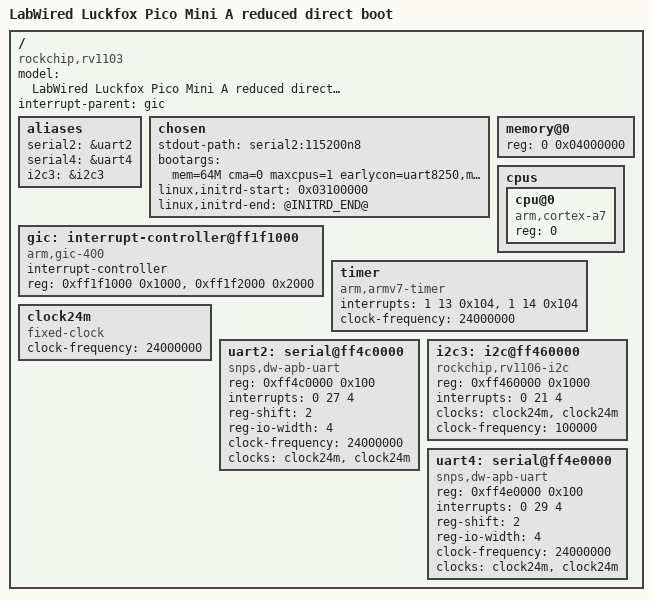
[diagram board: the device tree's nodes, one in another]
/dts-v1/;
/* Reduced direct boot: generic ARM DT fallback, no alternate SoC identity. */
/ {
    model = "LabWired Luckfox Pico Mini A reduced direct boot";
    compatible = "rockchip,rv1103";
    #address-cells = <1>;
    #size-cells = <1>;
    interrupt-parent = <&gic>;
    aliases { serial2 = &uart2; serial4 = &uart4; i2c3 = &i2c3; };
    chosen {
        stdout-path = "serial2:115200n8";
        bootargs = "mem=64M cma=0 maxcpus=1 earlycon=uart8250,mmio32,0xff4c0000,115200n8 console=ttyS2,115200n8 rdinit=/init loglevel=8 panic=-1 clocksource.arm_arch_timer.evtstrm=0";
        linux,initrd-start = <0x03100000>;
        linux,initrd-end = <@INITRD_END@>;
    };
    memory@0 { device_type = "memory"; reg = <0 0x04000000>; };
    cpus {
        #address-cells = <1>; #size-cells = <0>;
        cpu@0 { device_type = "cpu"; compatible = "arm,cortex-a7"; reg = <0>; };
    };
    gic: interrupt-controller@ff1f1000 {
        compatible = "arm,gic-400";
        #interrupt-cells = <3>;
        #address-cells = <0>;
        interrupt-controller;
        reg = <0xff1f1000 0x1000>, <0xff1f2000 0x2000>;
    };
    timer {
        compatible = "arm,armv7-timer";
        interrupts = <1 13 0x104>, <1 14 0x104>;
        clock-frequency = <24000000>;
    };
    clock24m: clock24m {
        compatible = "fixed-clock"; #clock-cells = <0>;
        clock-frequency = <24000000>;
    };
    uart2: serial@ff4c0000 {
        compatible = "snps,dw-apb-uart";
        reg = <0xff4c0000 0x100>; interrupts = <0 27 4>;
        reg-shift = <2>; reg-io-width = <4>; clock-frequency = <24000000>;
        clocks = <&clock24m>, <&clock24m>; clock-names = "baudclk", "apb_pclk";
        status = "okay";
    };
    i2c3: i2c@ff460000 {
        compatible = "rockchip,rv1106-i2c", "rockchip,rk3399-i2c";
        reg = <0xff460000 0x1000>; interrupts = <0 21 4>;
        #address-cells = <1>; #size-cells = <0>;
        clocks = <&clock24m>, <&clock24m>; clock-names = "i2c", "pclk";
        clock-frequency = <100000>; status = "okay";
    };
    uart4: serial@ff4e0000 {
        compatible = "snps,dw-apb-uart";
        reg = <0xff4e0000 0x100>; interrupts = <0 29 4>;
        reg-shift = <2>; reg-io-width = <4>; clock-frequency = <24000000>;
        clocks = <&clock24m>, <&clock24m>; clock-names = "baudclk", "apb_pclk";
        status = "okay";
    };
};
